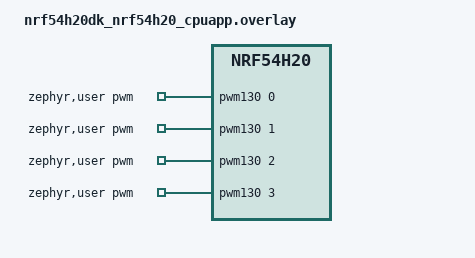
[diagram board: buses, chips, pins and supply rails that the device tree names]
/*
 * Copyright (c) 2026 Nordic Semiconductor ASA
 *
 * SPDX-License-Identifier: LicenseRef-Nordic-5-Clause
 */

/ {
	zephyr,user {
		pwms = <&pwm130 0 1600000 PWM_POLARITY_NORMAL>,
		       <&pwm130 1 1600000 PWM_POLARITY_NORMAL>,
		       <&pwm130 2 1600000 PWM_POLARITY_NORMAL>,
		       <&pwm130 3 1600000 PWM_POLARITY_NORMAL>;
	};
};
